# alb32r003x register map
Vendor: ALB; Series: ALB RT SoC
CPU: ALB XF, little endian
Registers are 32-bit, access not given, reset 0x0 unless marked. A register's access mark holds for its fields unless they carry their own. Offsets are from the block's base; [hi:lo] are bit positions; {n}, {i} and the like mark numbered series; 'fields as' and 'values as' point back to an identical list.

## CAN1
Base 0x22001000
Same registers: CAN2 0x22002000
{0x0+i} RBUF{i} 8-bit (i=0..2)
  [7:0] ID — ID Message
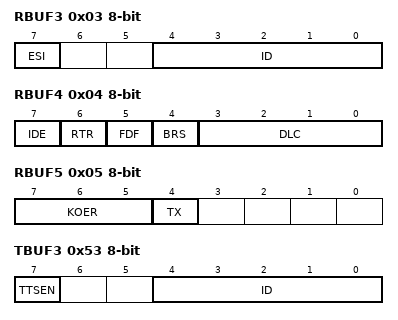
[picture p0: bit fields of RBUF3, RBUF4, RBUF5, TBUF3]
0x03 RBUF3 8-bit
  [7] ESI — The protocol machine automatically embeds the correct value of ESI into transmitted frames. ESI
  [4:0] ID — ID Message
0x04 RBUF4 8-bit
  [7] IDE — IDentifier Extension
  [6] RTR — Remote Transmission Request
  [5] FDF — CAN FD frame
  [4] BRS — Bit Rate Switch
  [3:0] DLC — DLC Frame Type Payload in Bytes
0x05 RBUF5 8-bit
  [7:5] KOER — KOER in RBUF has the same meaning as the bits KOER in register EALCAP. KOER in RBUF becomes
  [4] TX — Status bit TX in RBUF is set to 1 if the loop back mode is activated and the core has
0x06 RBUF6 8-bit
  [7:0] CYCLE_TIME — The time-stamp CYCLE_TIME will be stored in RBUF only in TTCAN mode.
0x07 RBUF7 8-bit
  fields as RBUF6
{0x0+i} RBUF{i} 8-bit (i=8..71)
  [7:0] D{i-7} — databyte{i-7}
{0x0+i} RBUF{i} 8-bit (i=72..76)
  [7:0] RTS{8i-569}_{8i-576} — The Reception Time Stamps (RTS) for CiA 603 time-stamping are stored for each received message at
{0x0+i} RBUF{i} 8-bit (i=77..79)
  [7:0] RTS{8i-569}_{8i-576} — The Reception Time Stamps (RTS) for CiA {i+527} time-stamping are stored for each received message at
{0x50+i} TBUF{i} 8-bit (i=0..2)
  [7:0] ID — ID value
0x53 TBUF3 8-bit
  [7] TTSEN — Transmit Time-Stamp ENable
  [4:0] ID — ID value
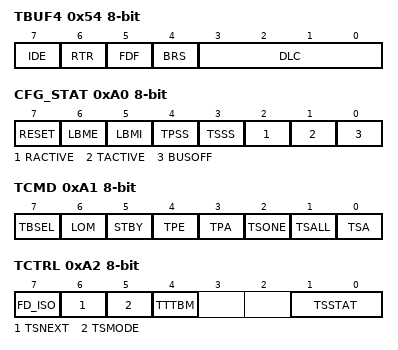
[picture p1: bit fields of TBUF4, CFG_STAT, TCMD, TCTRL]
0x54 TBUF4 8-bit
  [7] IDE — IDentifier Extension
  [6] RTR — Remote Transmission Request
  [5] FDF — CAN FD frame
  [4] BRS — Bit Rate Switch
  [3:0] DLC — The Data Length Code (DLC) in RBUF and TBUF defines the length of the payload - the number of
{0x50+i} TBUF{i} 8-bit (i=8..71)
  [7:0] D{i-7} — databyte{i-7}
0x98 TTS_L
  [31:0] TRANSMISSION_TIME_STAMP_L — Transmission Time Stamp
0x9C TTS_H
  [31:0] TRANSMISSION_TIME_STAMP_H — Transmission Time Stamp
0xA0 CFG_STAT 8-bit
  [7] RESET — RESET request bit
  [6] LBME — Loop Back Mode, External
  [5] LBMI — Loop Back Mode, Internal
  [4] TPSS — Transmission Primary Single Shot mode for PTB
  [3] TSSS — Transmission Secondary Single Shot mode for STB
  [2] RACTIVE — Reception ACTIVE (Receive Status bit)
  [1] TACTIVE — Transmission ACTIVE (Transmit Status bit)
  [0] BUSOFF
0xA1 TCMD 8-bit
  [7] TBSEL — Transmit Buffer Select
  [6] LOM — Listen Only Mode
  [5] STBY — Transceiver Standby Mode
  [4] TPE — Transmit Primary Enable
  [3] TPA — Transmit Primary Abort
  [2] TSONE — Transmit Secondary ONE frame
  [1] TSALL — Transmit Secondary ALL frames
  [0] TSA — Transmit Secondary Abort
0xA2 TCTRL 8-bit
  [7] FD_ISO — CAN FD ISO mode
  [6] TSNEXT — Transmit buffer Secondary NEXT
  [5] TSMODE — Transmit buffer Secondary operation MODE
  [4] TTTBM — TTCAN Transmit Buffer Mode
  [1:0] TSSTAT — Transmission Secondary STATus bits
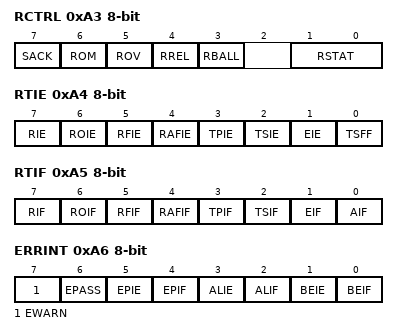
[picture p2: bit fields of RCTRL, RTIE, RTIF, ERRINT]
0xA3 RCTRL 8-bit
  [7] SACK — Self-ACKnowledge
  [6] ROM — Receive buffer Overflow Mode
  [5] ROV — Receive buffer OVerflow
  [4] RREL — Receive buffer RELease
  [3] RBALL — Receive Buffer stores ALL data frames
  [1:0] RSTAT — Receive buffer STATus
0xA4 RTIE 8-bit
  [7] RIE — Receive Interrupt Enable
  [6] ROIE — RB Overrun Interrupt Enable
  [5] RFIE — RB Full Interrupt Enable
  [4] RAFIE — RB Almost Full Interrupt Enable
  [3] TPIE — Transmission Primary Interrupt Enable
  [2] TSIE — Transmission Secondary Interrupt Enable
  [1] EIE — Error Interrupt Enable
  [0] TSFF — If TTEN=0 or TTTBM=0: Transmit Secondary buffer Full Flag
0xA5 RTIF 8-bit
  [7] RIF — Receive Interrupt Flag
  [6] ROIF — RB Overrun Interrupt Flag
  [5] RFIF — RB Full Interrupt Flag
  [4] RAFIF — RB Almost Full Interrupt Flag
  [3] TPIF — Transmission Primary Interrupt Flag
  [2] TSIF — Transmission Secondary Interrupt Flag
  [1] EIF — Error Interrupt Flag
  [0] AIF — Abort Interrupt Flag
0xA6 ERRINT 8-bit
  [7] EWARN — Error WARNing limit reached
  [6] EPASS — Error Passive mode active
  [5] EPIE — Error Passive Interrupt Enable
  [4] EPIF — Error Passive Interrupt Flag. EPIF will be activated if the error status changes from error
  [3] ALIE — Arbitration Lost Interrupt Enable
  [2] ALIF — Arbitration Lost Interrupt Flag
  [1] BEIE — Bus Error Interrupt Enable
  [0] BEIF — Bus Error Interrupt Flag
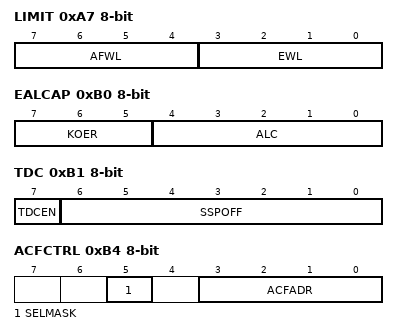
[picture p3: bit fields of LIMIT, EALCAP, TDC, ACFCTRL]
0xA7 LIMIT 8-bit
  [7:4] AFWL — receive buffer Almost Full Warning Limit
  [3:0] EWL — Programmable Error Warning Limit = (EWL+1)*8. Possible Limit values: 8, 16, ..., 128.
0xA8 S_Seg_1 8-bit
  [7:0] S_SEG_1 — Bit Timing Segment 1 (slow speed)
0xA9 S_Seg_2 8-bit
  [6:0] S_SEG_2 — Bit Timing Segment 2 (slow speed)
0xAA S_SJW 8-bit
  [6:0] S_SJW — Synchronization Jump Width (slow speed)
0xAB S_PRESC 8-bit
  [7:0] S_PRESC — Prescaler (slow speed)
0xAC F_Seg_1 8-bit
  [4:0] F_SEG_1 — Bit Timing Segment 1 (fast speed)
0xAD F_Seg_2 8-bit
  [3:0] F_SEG_2 — Bit Timing Segment 2 (fast speed)
0xAE F_SJW 8-bit
  [3:0] F_SJW — Synchronization Jump Width (fast speed)
0xAF F_PRESC 8-bit
  [7:0] F_PRESC — Prescaler (fast speed)
0xB0 EALCAP 8-bit
  [7:5] KOER — Kind Of ERror (Error code)
  [4:0] ALC — Arbitration Lost Capture (bit position in the frame
0xB1 TDC 8-bit
  [7] TDCEN — Transmitter Delay Compensation ENable
  [6:0] SSPOFF — Secondary Sample Point OFFset
0xB2 RECNT 8-bit
  [7:0] RECNT — Receive Error CouNT (number of errors during reception)
0xB3 TECNT 8-bit
  [7:0] TECNT — Transmit Error CouNT (number of errors during transmission) TECNT is incremented and decremented as defined
0xB4 ACFCTRL 8-bit
  [5] SELMASK — SELect acceptance MASK
  [3:0] ACFADR — acceptance filter address
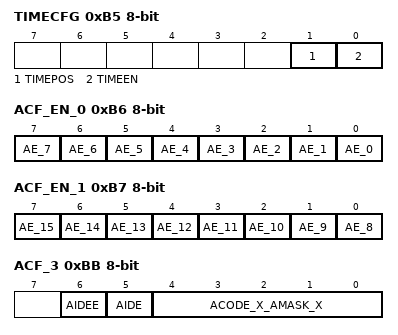
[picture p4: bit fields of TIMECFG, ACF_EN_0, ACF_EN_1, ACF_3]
0xB5 TIMECFG 8-bit
  [1] TIMEPOS — TIME-stamping POSition
  [0] TIMEEN — TIME-stamping ENable
0xB6 ACF_EN_0 8-bit
  [n] AE_{n} (n=0..7) — Acceptance filter Enable
0xB7 ACF_EN_1 8-bit
  [n-8] AE_{n} (n=8..15) — Acceptance filter Enable
{0xB8+i} ACF_{i} 8-bit (i=0..2)
  [7:0] ACODE_X_AMASK_X — Acceptance MASK
0xBB ACF_3 8-bit
  [6] AIDEE — Acceptance mask IDE bit check enable
  [5] AIDE — Acceptance mask IDE bit value
  [4:0] ACODE_X_AMASK_X — Acceptance MASK
0xBC VER_0 8-bit
  [7:0] VERSION — Version of CAN-CTRL, given as decimal value. VER_1 holds the major version and
0xBD VER_1 8-bit
  fields as VER_0
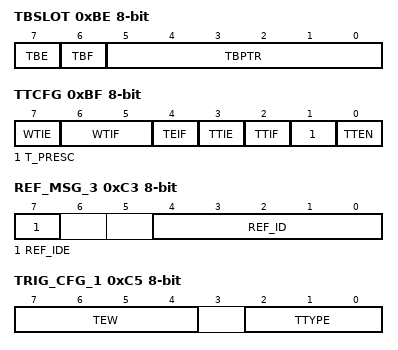
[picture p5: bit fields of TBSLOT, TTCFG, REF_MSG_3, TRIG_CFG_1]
0xBE TBSLOT 8-bit
  [7] TBE — set TB slot to “Empty”
  [6] TBF — set TB slot to “Filled”
  [5:0] TBPTR — Pointer to a TB message slot.
0xBF TTCFG 8-bit
  [7] WTIE — Watch Trigger Interrupt Enable
  [6:5] WTIF — Watch Trigger Interrupt Flag
  [4] TEIF — Trigger Error Interrupt Flag
  [3] TTIE — Time Trigger Interrupt Enable
  [2] TTIF — Time Trigger Interrupt Flag
  [1] T_PRESC — TTCAN Timer PRESCaler
  [0] TTEN — Time Trigger Enable
{0xC0+i} REF_MSG_{i} 8-bit (i=0..2)
  [7:0] REF_ID — REFerence message IDentifier.
0xC3 REF_MSG_3 8-bit
  [7] REF_IDE — REFerence message IDE bit.
  [4:0] REF_ID — REFerence message IDentifier.
0xC4 TRIG_CFG_0 8-bit
  [5:0] TTPTR — Transmit Trigger TB slot Pointer
0xC5 TRIG_CFG_1 8-bit
  [7:4] TEW — Transmit Enable Window
  [2:0] TTYPE — Trigger Type
0xC6 TT_TRIG_0 8-bit
  [7:0] TT_TRIG — Trigger Time
0xC7 TT_TRIG_1 8-bit
  [7:0] TT_TRIG — Trigger Time
0xC8 TT_WTRIG_0 8-bit
  [7:0] TT_WTRIG — Watch Trigger Time
0xC9 TT_WTRIG_1 8-bit
  [7:0] TT_WTRIG — Watch Trigger Time
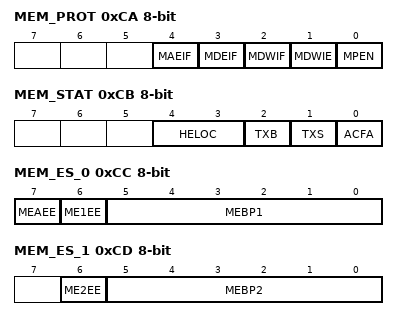
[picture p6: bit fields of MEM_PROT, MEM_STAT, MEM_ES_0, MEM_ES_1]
0xCA MEM_PROT 8-bit
  [4] MAEIF — Memory: Address Error Interrupt Flag
  [3] MDEIF — Memory: Data Error Interrupt Flag
  [2] MDWIF — Memory: Data Warning Interrupt Flag
  [1] MDWIE — Memory: Data Warning Interrupt Enable
  [0] MPEN — Memory Protection Enable
0xCB MEM_STAT 8-bit
  [4:3] HELOC — Host side memory error location
  [2] TXB — Transmission Block
  [1] TXS — Transmission Stop
  [0] ACFA — Acceptance Filter Accept
0xCC MEM_ES_0 8-bit
  [7] MEAEE — Memory Error: Address Error Enable
  [6] ME1EE — Memory Error: 1st Error Enable
  [5:0] MEBP1 — Memory Error: Bit Position 1
0xCD MEM_ES_1 8-bit
  [6] ME2EE — Memory Error: 2nd Error Enable
  [5:0] MEBP2 — Memory Error: Bit Position 2
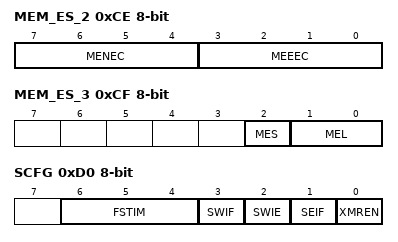
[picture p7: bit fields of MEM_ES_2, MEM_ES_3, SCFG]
0xCE MEM_ES_2 8-bit
  [7:4] MENEC — Memory Error: No Error Counter
  [3:0] MEEEC — Memory Error: Error Enable Counter
0xCF MEM_ES_3 8-bit
  [2] MES — Memory Error Side
  [1:0] MEL — Memory Error Location
0xD0 SCFG 8-bit
  [6:4] FSTIM — Fault Stimulation
  [3] SWIF — DMR / TMR: Safety warning interrupt flag
  [2] SWIE — DMR / TMR: Safety Warning Interrupt Enable
  [1] SEIF — DMR / TMR: Safety Error Interrupt Flag
  [0] XMREN — DMR / TMR enable
